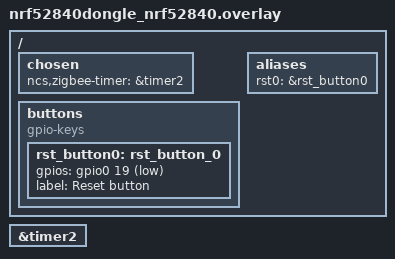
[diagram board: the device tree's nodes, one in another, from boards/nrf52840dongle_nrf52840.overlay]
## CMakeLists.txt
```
#
# Copyright (c) 2024 Nordic Semiconductor ASA
#
# SPDX-License-Identifier: LicenseRef-Nordic-5-Clause
#

cmake_minimum_required(VERSION 3.20.0)

find_package(Zephyr REQUIRED HINTS $ENV{ZEPHYR_BASE})

project("Zigbee application with Zigbee shell")

# NORDIC SDK APP START
target_sources(app PRIVATE
  src/main.c
)

target_include_directories(app PRIVATE include)
# NORDIC SDK APP END
```

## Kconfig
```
#
# Copyright (c) 2025 Nordic Semiconductor ASA
#
# SPDX-License-Identifier: LicenseRef-Nordic-5-Clause
#

source "Kconfig.zephyr"

menuconfig ZIGBEE_SHELL_USB
	bool "USB support for Zigbee shell"
	depends on DT_HAS_ZEPHYR_CDC_ACM_UART_ENABLED
	select USB_DEVICE_STACK_NEXT
	select USBD_CDC_ACM_CLASS
	select USBD_SHELL
	select UART_LINE_CTRL
	select STDOUT_CONSOLE
	select SHELL_BACKEND_SERIAL_CHECK_DTR
	help
	  Enable USB CDC ACM support for Zigbee shell interface.
	  This allows using the shell over USB instead of UART.
	  Only available on boards with USB device controller support.

if ZIGBEE_SHELL_USB

config ZIGBEE_SHELL_USB_VID
	hex "USB Vendor ID"
	default 0x2fe3
	help
	  USB Vendor ID for the Zigbee shell device.
	  Default uses Zephyr project VID (for samples only).

config ZIGBEE_SHELL_USB_PID
	hex "USB Product ID"
	default 0x0100
	help
	  USB Product ID for the Zigbee shell device.

config ZIGBEE_SHELL_USB_MAX_POWER
	int "USB device max power consumption (mA)"
	default 100
	range 2 500
	help
	  Maximum power consumption of the USB device in milliamperes.

config ZIGBEE_SHELL_USB_MANUFACTURER
	string "USB device manufacturer string"
	default "Nordic Semiconductor ASA"
	help
	  USB device manufacturer string descriptor.

config ZIGBEE_SHELL_USB_PRODUCT
	string "USB device product string"
	default "Zigbee Shell"
	help
	  USB device product string descriptor.

endif # ZIGBEE_SHELL_USB
```

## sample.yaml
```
sample:
  description: Zigbee application that includes all Zigbee shell commands
  name: Zigbee application with Zigbee shell
common:
  tags:
    - sysbuild
    - ci_build
    - shell
    - ci_samples_zigbee
tests:
  sample.zigbee.shell:
    build_only: true
    sysbuild: true
    integration_platforms:
      - nrf52840dk/nrf52840
      - nrf5340dk/nrf5340/cpuapp
      - nrf54l15dk/nrf54l15/cpuapp
      - nrf54lc10dk/nrf54lc10a/cpuapp
      - nrf54lm20dk/nrf54lm20b/cpuapp
    platform_allow:
      - nrf52840dk/nrf52840
      - nrf5340dk/nrf5340/cpuapp
      - nrf54l15dk/nrf54l10/cpuapp
      - nrf54l15dk/nrf54l15/cpuapp
      - nrf54lc10dk/nrf54lc10a/cpuapp
      - nrf54lm20dk/nrf54lm20a/cpuapp
      - nrf54lm20dk/nrf54lm20b/cpuapp
  sample.zigbee.shell.demo_commissioning:
    sysbuild: true
    build_only: true
    extra_args:
      - SNIPPET=zigbee_demo_commissioning
    integration_platforms:
      - nrf52840dk/nrf52840
      - nrf5340dk/nrf5340/cpuapp
      - nrf54l15dk/nrf54l15/cpuapp
      - nrf54lc10dk/nrf54lc10a/cpuapp
      - nrf54lm20dk/nrf54lm20b/cpuapp
    platform_allow:
      - nrf52840dk/nrf52840
      - nrf5340dk/nrf5340/cpuapp
      - nrf54l15dk/nrf54l10/cpuapp
      - nrf54l15dk/nrf54l15/cpuapp
      - nrf54lc10dk/nrf54lc10a/cpuapp
      - nrf54lm20dk/nrf54lm20a/cpuapp
      - nrf54lm20dk/nrf54lm20b/cpuapp
  sample.zigbee.shell.usb:
    sysbuild: true
    build_only: true
    integration_platforms:
      - nrf52840dongle/nrf52840
      - nrf5340dk/nrf5340/cpuapp
      - nrf54lm20dk/nrf54lm20b/cpuapp
      - nrf54lm20dongle/nrf54lm20b/cpuapp
    platform_allow:
      - nrf52840dk/nrf52840
      - nrf52840dongle/nrf52840
      - nrf5340dk/nrf5340/cpuapp
      - nrf54lm20dk/nrf54lm20a/cpuapp
      - nrf54lm20dk/nrf54lm20b/cpuapp
      - nrf54lm20dongle/nrf54lm20b/cpuapp
    extra_args:
      - FILE_SUFFIX=usb
  sample.zigbee.shell.usb.demo_commissioning:
    sysbuild: true
    build_only: true
    extra_args:
      - FILE_SUFFIX=usb
      - SNIPPET=zigbee_demo_commissioning
    integration_platforms:
      - nrf52840dk/nrf52840
      - nrf52840dongle/nrf52840
      - nrf5340dk/nrf5340/cpuapp
      - nrf54lm20dk/nrf54lm20b/cpuapp
      - nrf54lm20dongle/nrf54lm20b/cpuapp
    platform_allow:
      - nrf52840dk/nrf52840
      - nrf52840dongle/nrf52840
      - nrf5340dk/nrf5340/cpuapp
      - nrf54lm20dk/nrf54lm20a/cpuapp
      - nrf54lm20dk/nrf54lm20b/cpuapp
      - nrf54lm20dongle/nrf54lm20b/cpuapp
```

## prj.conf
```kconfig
#
# Copyright (c) 2024 Nordic Semiconductor ASA
#
# SPDX-License-Identifier: LicenseRef-Nordic-5-Clause
#

CONFIG_NCS_SAMPLES_DEFAULTS=y

# LOG configuration
CONFIG_LOG_CMDS=y
CONFIG_LOG_MODE_DEFERRED=y
CONFIG_LOG_BUFFER_SIZE=4096
CONFIG_LOG_PROCESS_THREAD_STACK_SIZE=1024
CONFIG_LOG_PROCESS_THREAD_STARTUP_DELAY_MS=1000

# Configure serial
CONFIG_UART_INTERRUPT_DRIVEN=y
CONFIG_SERIAL=y
CONFIG_GPIO=y

# Make sure printk is not printing to the UART console
CONFIG_CONSOLE=y
CONFIG_UART_CONSOLE=y

CONFIG_HEAP_MEM_POOL_SIZE=2048
CONFIG_MAIN_THREAD_PRIORITY=7

CONFIG_ZIGBEE_ADD_ON=y
CONFIG_ZIGBEE_APP_UTILS=y
CONFIG_ZIGBEE_ROLE_ROUTER=y

# Enable DK LED and Buttons library
CONFIG_DK_LIBRARY=y
# Zigbee shell
CONFIG_ZIGBEE_SHELL=y
CONFIG_ZIGBEE_SHELL_DEBUG_CMD=y
CONFIG_ZIGBEE_SHELL_ENDPOINT=64

# Increase RX serial ring buffer
CONFIG_SHELL_BACKEND_SERIAL_RX_RING_BUFFER_SIZE=128
```

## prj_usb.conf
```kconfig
#
# Copyright (c) 2025 Nordic Semiconductor ASA
#
# SPDX-License-Identifier: LicenseRef-Nordic-5-Clause
#

CONFIG_NCS_SAMPLES_DEFAULTS=y

# LOG configuration
CONFIG_LOG_CMDS=y
CONFIG_LOG_MODE_DEFERRED=y
CONFIG_LOG_BUFFER_SIZE=4096
CONFIG_LOG_PROCESS_THREAD_STACK_SIZE=1024
CONFIG_LOG_PROCESS_THREAD_STARTUP_DELAY_MS=1000

# Configure serial
CONFIG_UART_INTERRUPT_DRIVEN=y
CONFIG_SERIAL=y
CONFIG_GPIO=y

# Make sure printk is not printing to the UART console
CONFIG_CONSOLE=y
CONFIG_UART_CONSOLE=y

CONFIG_HEAP_MEM_POOL_SIZE=2048
CONFIG_MAIN_THREAD_PRIORITY=7

CONFIG_ZIGBEE_ADD_ON=y
CONFIG_ZIGBEE_APP_UTILS=y
CONFIG_ZIGBEE_ROLE_ROUTER=y

# Enable DK LED and Buttons library
CONFIG_DK_LIBRARY=y
# Networking
CONFIG_NET_IPV6=n
CONFIG_NET_IP_ADDR_CHECK=n
CONFIG_NET_UDP=n

# Zigbee shell
CONFIG_ZIGBEE_SHELL=y
CONFIG_ZIGBEE_SHELL_DEBUG_CMD=y
CONFIG_ZIGBEE_SHELL_ENDPOINT=64

# Increase RX serial ring buffer
CONFIG_SHELL_BACKEND_SERIAL_RX_RING_BUFFER_SIZE=128

# Use new USB stack with CDC ACM initialized at boot
CONFIG_USB_DEVICE_STACK_NEXT=y
CONFIG_CDC_ACM_SERIAL_INITIALIZE_AT_BOOT=y
CONFIG_CDC_ACM_SERIAL_VID=0x1915
CONFIG_CDC_ACM_SERIAL_PID=0x0100
CONFIG_CDC_ACM_SERIAL_MANUFACTURER_STRING="Nordic Semiconductor ASA"
CONFIG_CDC_ACM_SERIAL_PRODUCT_STRING="Zigbee Shell"


CONFIG_USBD_LOG_LEVEL_WRN=y
CONFIG_UDC_DRIVER_LOG_LEVEL_WRN=y
# Disable USB CDC ACM logging to avoid conflicts when console/shell uses the same interface
CONFIG_USBD_CDC_ACM_LOG_LEVEL_OFF=y

# Enable this to duplicate Zephyr logs to default Logger serial backend,
# usually connected to on-board JLink device.
# CONFIG_LOG_BACKEND_UART=y
```

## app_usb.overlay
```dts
/*
 * Copyright (c) 2025 Nordic Semiconductor ASA
 *
 * SPDX-License-Identifier: LicenseRef-Nordic-5-Clause
 */

&zephyr_udc0 {
	cdc_acm_uart: cdc_acm_uart {
		compatible = "zephyr,cdc-acm-uart";
	};
};

/ {
	chosen {
		zephyr,shell-uart = &cdc_acm_uart;
	};
};
```

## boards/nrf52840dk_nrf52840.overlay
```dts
/*
 * Copyright (c) 2025 Nordic Semiconductor ASA
 *
 * SPDX-License-Identifier: LicenseRef-Nordic-5-Clause
 */

#include <nrf52840_partitions.dtsi>

/ {
	chosen {
		ncs,zigbee-timer = &timer2;
	};
};

&timer2 {
	status = "okay";
};
```

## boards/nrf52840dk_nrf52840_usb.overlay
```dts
/*
 * Copyright (c) 2025 Nordic Semiconductor ASA
 *
 * SPDX-License-Identifier: LicenseRef-Nordic-5-Clause
 */

#include "nrf52840dk_nrf52840.overlay"
#include "../app_usb.overlay"
```

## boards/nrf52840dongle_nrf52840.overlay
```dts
/*
 * Copyright (c) 2025 Nordic Semiconductor ASA
 *
 * SPDX-License-Identifier: LicenseRef-Nordic-5-Clause
 */

#include <nrf52840dongle_partitions.dtsi>

/ {
	chosen {
		ncs,zigbee-timer = &timer2;
	};

	buttons {
		compatible = "gpio-keys";

		rst_button0: rst_button_0 {
			gpios = <&gpio0 19 (GPIO_PULL_UP | GPIO_ACTIVE_LOW)>;
			label = "Reset button";
		};
	};

	aliases {
		rst0 = &rst_button0;
	};
};

&timer2 {
	status = "okay";
};
```

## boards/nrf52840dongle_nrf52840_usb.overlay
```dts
/*
 * Copyright (c) 2026 Nordic Semiconductor ASA
 *
 * SPDX-License-Identifier: LicenseRef-Nordic-5-Clause
 *
 */

#include "nrf52840dongle_nrf52840.overlay"

/*
 * For nrf52840dongle the board already includes cdc_acm_serial.dtsi which
 * defines board_cdc_acm_uart and sets zephyr,shell-uart. Do not include
 * app_usb.overlay here or it would add a duplicate cdc_acm_uart node and
 * override shell-uart to it.
 */
```

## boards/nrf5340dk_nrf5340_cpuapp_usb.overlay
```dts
/*
 * Copyright (c) 2025 Nordic Semiconductor ASA
 *
 * SPDX-License-Identifier: LicenseRef-Nordic-5-Clause
 */

#include <nrf5340_cpuapp_partitions.dtsi>

&zephyr_udc0 {
	cdc_acm_uart0: cdc_acm_uart0 {
		compatible = "zephyr,cdc-acm-uart";
	};
};

/ {
	chosen {
		ncs,zigbee-uart = &cdc_acm_uart0;
	};
};
```

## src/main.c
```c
/*
 * Copyright (c) 2024 Nordic Semiconductor ASA
 *
 * SPDX-License-Identifier: LicenseRef-Nordic-5-Clause
 */

/** @file
 *
 * @brief Zigbee shell sample.
 */

#include <zephyr/kernel.h>
#include <zephyr/logging/log.h>
#include <dk_buttons_and_leds.h>

#include <zboss_api.h>
#include <zigbee/zigbee_error_handler.h>
#include <zigbee/zigbee_app_utils.h>
#include <zigbee/zigbee_app_io_shell.h>
#include <zb_nrf_platform.h>

/* Device endpoint, used to receive ZCL commands. */
#define APP_ZIGBEE_ENDPOINT              CONFIG_ZIGBEE_SHELL_ENDPOINT

/* Type of power sources available for the device.
 * For possible values see section 3.2.2.2.8 of ZCL specification.
 */
#define SHELL_INIT_BASIC_POWER_SOURCE    ZB_ZCL_BASIC_POWER_SOURCE_DC_SOURCE

/* LED indicating that device successfully joined Zigbee network. */
#define ZIGBEE_NETWORK_STATE_LED         DK_LED3

/* LED used for device identification. */
#ifdef CONFIG_BOARD_NRF52840DONGLE_NRF52840
#define IDENTIFY_LED                     DK_LED1
#else
#define IDENTIFY_LED                     DK_LED4
#endif

/* Button used to enter the Identify mode. */
#ifdef CONFIG_BOARD_NRF52840DONGLE_NRF52840
#define IDENTIFY_MODE_BUTTON             DK_BTN1_MSK
#elif defined(CONFIG_BOARD_NRF54LM20DONGLE)
#define IDENTIFY_MODE_BUTTON             DK_BTN2_MSK
#else
#define IDENTIFY_MODE_BUTTON             DK_BTN4_MSK
#endif

LOG_MODULE_REGISTER(app, LOG_LEVEL_INF);

/* Main application customizable context.
 * Stores all settings and static values.
 */
struct zb_device_ctx {
	zb_zcl_basic_attrs_t basic_attr;
	zb_zcl_identify_attrs_t identify_attr;
};

/* Zigbee device application context storage. */
static struct zb_device_ctx dev_ctx;

ZB_ZCL_DECLARE_IDENTIFY_ATTRIB_LIST(
	identify_attr_list,
	&dev_ctx.identify_attr.identify_time);

ZB_ZCL_DECLARE_BASIC_ATTRIB_LIST(
	basic_attr_list,
	&dev_ctx.basic_attr.zcl_version,
	&dev_ctx.basic_attr.power_source);

ZB_HA_DECLARE_RANGE_EXTENDER_CLUSTER_LIST(
	app_template_clusters,
	basic_attr_list,
	identify_attr_list);

ZB_HA_DECLARE_RANGE_EXTENDER_EP(
	app_zigbee_ep,
	APP_ZIGBEE_ENDPOINT,
	app_template_clusters);

ZBOSS_DECLARE_DEVICE_CTX_1_EP(
	app_zigbee_ctx,
	app_zigbee_ep);


/**@brief Function for initializing all clusters attributes. */
static void app_clusters_attr_init(void)
{
	/* Basic cluster attributes data */
	dev_ctx.basic_attr.zcl_version = ZB_ZCL_VERSION;
	dev_ctx.basic_attr.power_source = SHELL_INIT_BASIC_POWER_SOURCE;

	/* Identify cluster attributes data. */
	dev_ctx.identify_attr.identify_time =
		ZB_ZCL_IDENTIFY_IDENTIFY_TIME_DEFAULT_VALUE;
}

/**@brief Function to toggle the identify LED
 *
 * @param  bufid  Unused parameter, required by ZBOSS scheduler API.
 */
static void toggle_identify_led(zb_cb_param_t param)
{
	static int blink_status;

	zigbee_app_io_set_led(IDENTIFY_LED, (++blink_status) % 2);
	ZB_SCHEDULE_APP_ALARM(toggle_identify_led, param, ZB_MILLISECONDS_TO_BEACON_INTERVAL(100));
}

/**@brief Function to handle identify notification events on the first endpoint.
 *
 * @param  param  ZB_TRUE when identify starts, ZB_FALSE when it stops.
 */
static void identify_cb(zb_cb_param_t param)
{
	zb_ret_t zb_err_code;

	if (param) {
		/* Schedule a self-scheduling function that will toggle the LED */
		ZB_SCHEDULE_APP_CALLBACK(toggle_identify_led, param);
	} else {
		/* Cancel the toggling function alarm and turn off LED */
		zb_err_code = ZB_SCHEDULE_APP_ALARM_CANCEL(toggle_identify_led, ZB_ALARM_ANY_PARAM);
		ZVUNUSED(zb_err_code);

		zigbee_app_io_set_led(IDENTIFY_LED, 0);
	}
}

/**@brief Starts identifying the device.
 *
 * @param  bufid  Unused parameter, required by ZBOSS scheduler API.
 */
static void start_identifying(zb_cb_param_t param)
{
	ZVUNUSED(param);

	if (ZB_JOINED()) {
		/* Check if endpoint is in identifying mode,
		 * if not put desired endpoint in identifying mode.
		 */
		if (dev_ctx.identify_attr.identify_time ==
		    ZB_ZCL_IDENTIFY_IDENTIFY_TIME_DEFAULT_VALUE) {

			zb_ret_t zb_err_code = zb_bdb_finding_binding_target(
				APP_ZIGBEE_ENDPOINT);

			if (zb_err_code == RET_OK) {
				LOG_INF("Enter identify mode");
			} else if (zb_err_code == RET_INVALID_STATE) {
				LOG_WRN("RET_INVALID_STATE - Cannot enter identify mode");
			} else {
				ZB_ERROR_CHECK(zb_err_code);
			}
		} else {
			LOG_INF("Cancel identify mode");
			zb_bdb_finding_binding_target_cancel();
		}
	} else {
		LOG_WRN("Device not in a network - cannot enter identify mode");
	}
}

/**@brief Callback for button events.
 *
 * @param[in]   button_state  Bitmask containing buttons state.
 * @param[in]   has_changed   Bitmask containing buttons that have changed their state.
 */
static void button_changed(uint32_t button_state, uint32_t has_changed)
{
	if (IDENTIFY_MODE_BUTTON & has_changed) {
		if (IDENTIFY_MODE_BUTTON & button_state) {
			/* Button changed its state to pressed */
		} else {
			/* Button changed its state to released */
			ZB_SCHEDULE_APP_CALLBACK(start_identifying, 0);
		}
	}
}

/**@brief Function for initializing LEDs and Buttons. */
static void configure_gpio(void)
{
	int err;

	err = dk_buttons_init(button_changed);
	if (err) {
		LOG_ERR("Cannot init buttons (err: %d)", err);
	}

	err = dk_leds_init();
	if (err) {
		LOG_ERR("Cannot init LEDs (err: %d)", err);
	}

	zigbee_app_io_shell_init(button_changed);
}

/**@brief Zigbee stack event handler.
 *
 * @param[in]   bufid   Reference to the Zigbee stack buffer used to pass signal.
 */
void zboss_signal_handler(zb_cb_param_t param)
{
	zb_zdo_app_signal_hdr_t *sig_handler = NULL;
	zb_zdo_app_signal_type_t sig = zb_get_app_signal(param, &sig_handler);
	zb_ret_t status = ZB_GET_APP_SIGNAL_STATUS(param);

	/* Update network status LED. */
	zigbee_led_status_update(param, ZIGBEE_NETWORK_STATE_LED);

	switch (sig) {
	case ZB_ZDO_SIGNAL_LEAVE:
		if (status == RET_OK) {
			zb_zdo_signal_leave_params_t *leave_params =
				ZB_ZDO_SIGNAL_GET_PARAMS(
					sig_handler,
					zb_zdo_signal_leave_params_t);
			LOG_INF("Network left (leave type: %d)",
				leave_params->leave_type);
			/* Let the user decide when to start the next formation
			 * or rejoin procedure.
			 */
		} else {
			LOG_ERR("Unable to leave network (status: %d)", status);
		}
		break;
	default:
		/* Call default signal handler. */
		ZB_ERROR_CHECK(zigbee_default_signal_handler(param));
		break;
	}

	if (param) {
		zb_buf_free(param);
	}
}

int main(void)
{
	LOG_INF("Starting Zigbee R23 Shell application");

	/* Initialize */
	configure_gpio();

	/* Register device context (endpoints). */
	ZB_AF_REGISTER_DEVICE_CTX(&app_zigbee_ctx);

	app_clusters_attr_init();

	/* Register handlers to identify notifications */
	ZB_AF_SET_IDENTIFY_NOTIFICATION_HANDLER(APP_ZIGBEE_ENDPOINT, identify_cb);

	LOG_INF("Zigbee R23 Shell application started");

	return 0;
}
```
